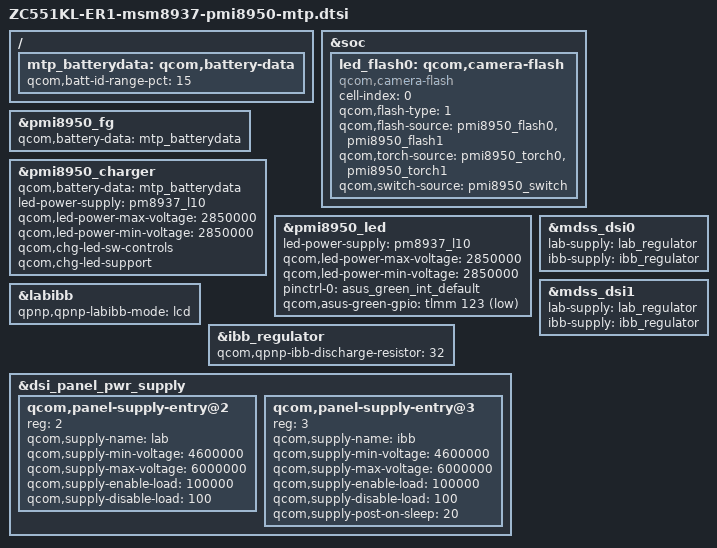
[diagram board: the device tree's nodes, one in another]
/*
 * Copyright (c) 2015-2016, The Linux Foundation. All rights reserved.
 *
 * This program is free software; you can redistribute it and/or modify
 * it under the terms of the GNU General Public License version 2 and
 * only version 2 as published by the Free Software Foundation.
 *
 * This program is distributed in the hope that it will be useful,
 * but WITHOUT ANY WARRANTY; without even the implied warranty of
 * MERCHANTABILITY or FITNESS FOR A PARTICULAR PURPOSE.  See the
 * GNU General Public License for more details.
 */

#include "msm-pmi8950.dtsi"
#include "ZC551KL-ER1-msm8937-mtp.dtsi"
#include "msm8937-audio-mtp.dtsi"

&soc {
	led_flash0: qcom,camera-flash {
		cell-index = <0>;
		compatible = "qcom,camera-flash";
		qcom,flash-type = <1>;
		qcom,flash-source = <&pmi8950_flash0 &pmi8950_flash1>;
		qcom,torch-source = <&pmi8950_torch0 &pmi8950_torch1>;
		qcom,switch-source = <&pmi8950_switch>;
	};
};

/{
	mtp_batterydata: qcom,battery-data {
		qcom,batt-id-range-pct = <15>;
		#include "batterydata-itech-3000mah.dtsi"
		#include "batterydata-ascent-3450mAh.dtsi"
	};
};

&pmi8950_fg {
	qcom,battery-data = <&mtp_batterydata>;
};

&pmi8950_charger {
	qcom,battery-data = <&mtp_batterydata>;
	led-power-supply=<&pm8937_l10>;
	qcom,led-power-max-voltage=<2850000>;
	qcom,led-power-min-voltage=<2850000>;
	qcom,chg-led-sw-controls;
	qcom,chg-led-support;
};

&pmi8950_led {
	led-power-supply=<&pm8937_l10>;
	qcom,led-power-max-voltage=<2850000>;
    qcom,led-power-min-voltage=<2850000>;
	pinctrl-names = "asus_led_gpio";
	pinctrl-0 = <&asus_green_int_default>;
	qcom,asus-green-gpio = <&tlmm 123 0x1>;
};

&mdss_dsi0 {
	lab-supply = <&lab_regulator>;
	ibb-supply = <&ibb_regulator>;
};

&mdss_dsi1 {
	lab-supply = <&lab_regulator>;
	ibb-supply = <&ibb_regulator>;
};

&labibb {
	status = "ok";
	qpnp,qpnp-labibb-mode = "lcd";
};

&ibb_regulator {
	qcom,qpnp-ibb-discharge-resistor = <32>;
};

&dsi_panel_pwr_supply {
	qcom,panel-supply-entry@2 {
		reg = <2>;
		qcom,supply-name = "lab";
		qcom,supply-min-voltage = <4600000>;
		qcom,supply-max-voltage = <6000000>;
		qcom,supply-enable-load = <100000>;
		qcom,supply-disable-load = <100>;
	};

	qcom,panel-supply-entry@3 {
		reg = <3>;
		qcom,supply-name = "ibb";
		qcom,supply-min-voltage = <4600000>;
		qcom,supply-max-voltage = <6000000>;
		qcom,supply-enable-load = <100000>;
		qcom,supply-disable-load = <100>;
		qcom,supply-post-on-sleep = <20>;
	};
};
